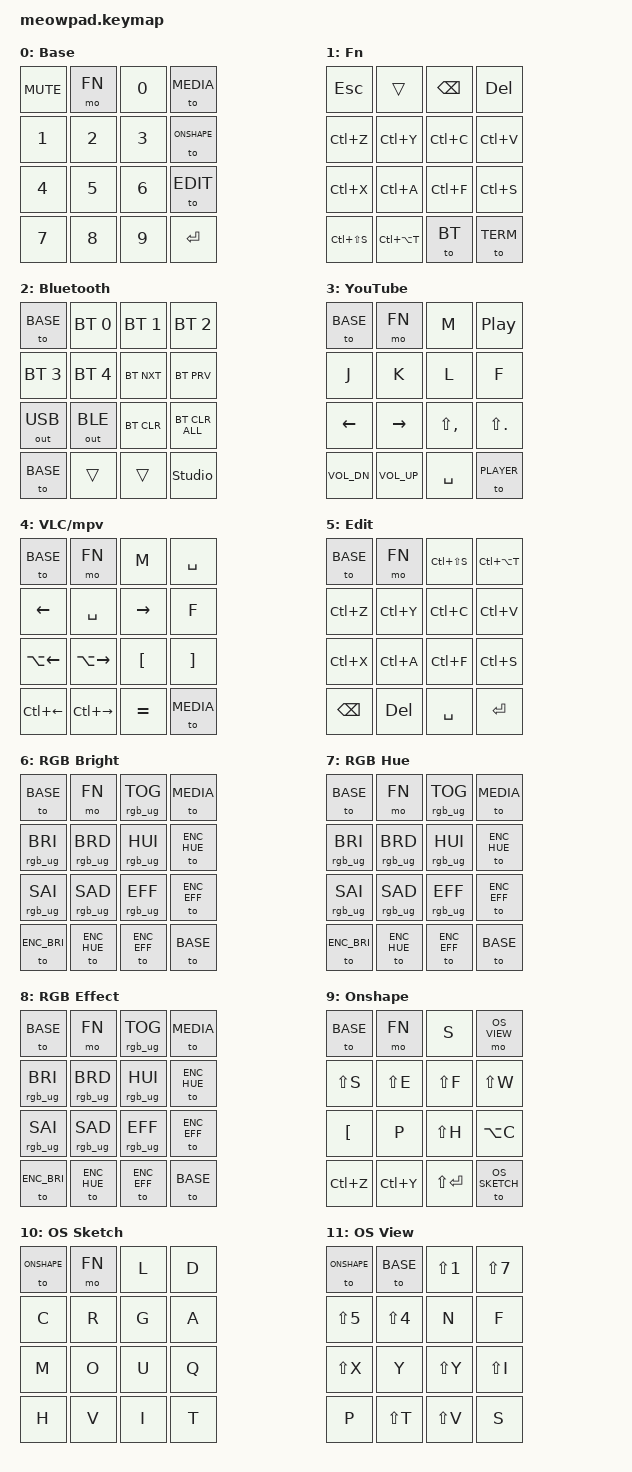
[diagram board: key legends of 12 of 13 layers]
#include <behaviors.dtsi>
#include <dt-bindings/zmk/bt.h>
#include <dt-bindings/zmk/keys.h>
#include <dt-bindings/zmk/outputs.h>
#include <dt-bindings/zmk/rgb.h>

#define BASE       0
#define FN         1
#define BT         2
#define MEDIA      3
#define PLAYER     4
#define EDIT       5
#define ENC_BRI    6
#define ENC_HUE    7
#define ENC_EFF    8
#define ONSHAPE    9
#define OS_SKETCH  10
#define OS_VIEW    11
#define TERM       12

/*
 * Debug override for encoder bring-up. This keeps the shield overlay as-is
 * while forcing the tested P0.29/P0.31 pin order and a very obvious step rate.
 */
&encoder {
    a-gpios = <&pro_micro 20 (GPIO_ACTIVE_HIGH | GPIO_PULL_UP)>; /* D20/A2 -> P0.29 */
    b-gpios = <&pro_micro 21 (GPIO_ACTIVE_HIGH | GPIO_PULL_UP)>; /* D21/A3 -> P0.31 */
    steps = <80>;
};

/ {
    behaviors {
        rgb_encoder_bri: rgb_encoder_bri {
            compatible = "zmk,behavior-sensor-rotate";
            #sensor-binding-cells = <0>;
            bindings = <&rgb_ug RGB_BRI>, <&rgb_ug RGB_BRD>;
        };

        rgb_encoder_hue: rgb_encoder_hue {
            compatible = "zmk,behavior-sensor-rotate";
            #sensor-binding-cells = <0>;
            bindings = <&rgb_ug RGB_HUI>, <&rgb_ug RGB_HUD>;
        };

        rgb_encoder_eff: rgb_encoder_eff {
            compatible = "zmk,behavior-sensor-rotate";
            #sensor-binding-cells = <0>;
            bindings = <&rgb_ug RGB_EFF>, <&rgb_ug RGB_EFR>;
        };

        onshape_zoom_encoder: onshape_zoom_encoder {
            compatible = "zmk,behavior-sensor-rotate";
            #sensor-binding-cells = <0>;
            bindings = <&kp LS(Z)>, <&kp Z>;
        };
    };

    macros {
        term_fg: term_fg {
            compatible = "zmk,behavior-macro";
            #binding-cells = <0>;
            bindings = <&macro_tap &kp F &kp G &kp ENTER>;
        };

        term_ls: term_ls {
            compatible = "zmk,behavior-macro";
            #binding-cells = <0>;
            bindings = <&macro_tap &kp L &kp S &kp SPACE &kp MINUS &kp L &kp A &kp H &kp ENTER>;
        };

        term_cd_up: term_cd_up {
            compatible = "zmk,behavior-macro";
            #binding-cells = <0>;
            bindings = <&macro_tap &kp C &kp D &kp SPACE &kp DOT &kp DOT &kp ENTER>;
        };

        term_git_status: term_git_status {
            compatible = "zmk,behavior-macro";
            #binding-cells = <0>;
            bindings = <&macro_tap &kp G &kp I &kp T &kp SPACE &kp S &kp T &kp A &kp T &kp U &kp S &kp ENTER>;
        };
    };

    keymap {
        compatible = "zmk,keymap";

        /*
         * Physical cap legend shared by all layers:
         *
         * | knob | fn | 0 | m1 |
         * |  1   | 2  | 3 | m2 |
         * |  4   | 5  | 6 | m3 |
         * |  7   | 8  | 9 | m4 |
         */

        default_layer {
            display-name = "Base";
            /*
             * Base layer:
             *
             * |mute | fn | 0 | media |
             * |  1  | 2  | 3 | onshp |
             * |  4  | 5  | 6 | edit  |
             * |  7  | 8  | 9 | enter |
             *
             * Encoder rotate: volume up/down.
             */
            bindings = <
                &kp C_MUTE       &mo FN          &kp N0          &to MEDIA
                &kp N1           &kp N2          &kp N3          &to ONSHAPE
                &kp N4           &kp N5          &kp N6          &to EDIT
                &kp N7           &kp N8          &kp N9          &kp ENTER
            >;
            sensor-bindings = <&inc_dec_kp C_VOL_UP C_VOL_DN>;
        };


        fn_layer {
            /*
             * Function layer:
             *
             * |esc | --- | bspc | del  |
             * |undo| redo| copy | paste|
             * | cut| all | find | save |
             * |snip| term| bt   | term |
             */
            display-name = "Fn";
            bindings = <
                &kp ESC          &trans          &kp BSPC        &kp DEL
                &kp LC(Z)        &kp LC(Y)       &kp LC(C)       &kp LC(V)
                &kp LC(X)        &kp LC(A)       &kp LC(F)       &kp LC(S)
                &kp LC(LS(S))    &kp LC(LA(T))   &to BT          &to TERM
            >;
            sensor-bindings = <&inc_dec_kp C_VOL_UP C_VOL_DN>;
        };

        bluetooth_layer {
            /*
             * Bluetooth/output layer:
             *
             * |base | bt0 | bt1 | bt2     |
             * | bt3 | bt4 | next| prev    |
             * | usb | ble | clr | clr_all |
             * |base | --- | --- | studio  |
             */
            display-name = "Bluetooth";
            bindings = <
                &to BASE         &bt BT_SEL 0    &bt BT_SEL 1    &bt BT_SEL 2
                &bt BT_SEL 3     &bt BT_SEL 4    &bt BT_NXT      &bt BT_PRV
                &out OUT_USB     &out OUT_BLE    &bt BT_CLR      &bt BT_CLR_ALL
                &to BASE         &trans          &trans          &studio_unlock
            >;
            sensor-bindings = <&inc_dec_kp C_VOL_UP C_VOL_DN>;
        };

        media_layer {

            /*
             * YouTube/media layer:
             *
             * |base | fn | mute | play  |
             * |  j  | k  |  l   | full  |
             * |left |right| <   | >     |
             * |vol- |vol+| space| player|
             *
             * Encoder rotate: volume up/down.
             */
            display-name = "YouTube";
            bindings = <
                &to BASE         &mo FN          &kp M           &kp C_PP
                &kp J            &kp K           &kp L           &kp F
                &kp LEFT         &kp RIGHT       &kp LS(COMMA)   &kp LS(DOT)
                &kp C_VOL_DN     &kp C_VOL_UP    &kp SPACE       &to PLAYER
            >;
            sensor-bindings = <&inc_dec_kp C_VOL_UP C_VOL_DN>;
        };

        player_layer {

            /*
             * VLC/mpv player layer:
             *
             * |base | fn | mute | play  |
             * |left |space|right| full  |
             * |a-left|a-right| [ | ]    |
             * |c-left|c-right| = | media|
             *
             * Encoder rotate: volume up/down.
             */
            display-name = "VLC/mpv";
            bindings = <
                &to BASE         &mo FN          &kp M           &kp SPACE
                &kp LEFT         &kp SPACE       &kp RIGHT       &kp F
                &kp LA(LEFT)     &kp LA(RIGHT)   &kp LBKT        &kp RBKT
                &kp LC(LEFT)     &kp LC(RIGHT)   &kp EQUAL       &to MEDIA
            >;
            sensor-bindings = <&inc_dec_kp C_VOL_UP C_VOL_DN>;
        };

        edit_layer {

            /*
             * Edit layer:
             *
             * |base | fn | snip | term |
             * |undo |redo| copy |paste |
             * | cut | all| find |save  |
             * |bspc |del |space |enter |
             */
            display-name = "Edit";
            bindings = <
                &to BASE         &mo FN          &kp LC(LS(S))   &kp LC(LA(T))
                &kp LC(Z)        &kp LC(Y)       &kp LC(C)       &kp LC(V)
                &kp LC(X)        &kp LC(A)       &kp LC(F)       &kp LC(S)
                &kp BSPC         &kp DEL         &kp SPACE       &kp ENTER
            >;
            sensor-bindings = <&inc_dec_kp C_VOL_UP C_VOL_DN>;
        };

        encoder_brightness_layer {
            /*
             * RGB brightness mode:
             *
             * |base | fn | rgb  | media |
             * | bri | brd| hue+ | hue   |
             * | sat+| sat-| eff | effect|
             * | bri | hue| effect| base |
             *
             * Encoder rotate: brightness up/down.
             */
            display-name = "RGB Bright";
            bindings = <
                &to BASE         &mo FN          &rgb_ug RGB_TOG &to MEDIA
                &rgb_ug RGB_BRI  &rgb_ug RGB_BRD &rgb_ug RGB_HUI &to ENC_HUE
                &rgb_ug RGB_SAI  &rgb_ug RGB_SAD &rgb_ug RGB_EFF &to ENC_EFF
                &to ENC_BRI      &to ENC_HUE     &to ENC_EFF     &to BASE
            >;
            sensor-bindings = <&rgb_encoder_bri>;
        };

        encoder_hue_layer {
            /*
             * RGB hue mode.
             * Same key layout as RGB Bright; only the encoder action changes.
             * Encoder rotate: hue up/down.
             */
            display-name = "RGB Hue";
            bindings = <
                &to BASE         &mo FN          &rgb_ug RGB_TOG &to MEDIA
                &rgb_ug RGB_BRI  &rgb_ug RGB_BRD &rgb_ug RGB_HUI &to ENC_HUE
                &rgb_ug RGB_SAI  &rgb_ug RGB_SAD &rgb_ug RGB_EFF &to ENC_EFF
                &to ENC_BRI      &to ENC_HUE     &to ENC_EFF     &to BASE
            >;
            sensor-bindings = <&rgb_encoder_hue>;
        };

        encoder_effect_layer {
            /*
             * RGB effect mode.
             * Same key layout as RGB Bright; only the encoder action changes.
             * Encoder rotate: effect next/previous.
             */
            display-name = "RGB Effect";
            bindings = <
                &to BASE         &mo FN          &rgb_ug RGB_TOG &to MEDIA
                &rgb_ug RGB_BRI  &rgb_ug RGB_BRD &rgb_ug RGB_HUI &to ENC_HUE
                &rgb_ug RGB_SAI  &rgb_ug RGB_SAD &rgb_ug RGB_EFF &to ENC_EFF
                &to ENC_BRI      &to ENC_HUE     &to ENC_EFF     &to BASE
            >;
            sensor-bindings = <&rgb_encoder_eff>;
        };

        onshape_layer {
            /*
             * Onshape main layer:
             *
             * |base | fn |   s     | view |
             * |sh+s |sh+e| sh+f    | sh+w |
             * |  [  | p  | sh+h    | alt+c|
             * |undo |redo| sh+enter| sketch|
             *
             * Encoder rotate: zoom out/in.
             */
            display-name = "Onshape";
            bindings = <
                &to BASE         &mo FN          &kp S           &mo OS_VIEW
                &kp LS(S)        &kp LS(E)       &kp LS(F)       &kp LS(W)
                &kp LBKT         &kp P           &kp LS(H)       &kp LA(C)
                &kp LC(Z)        &kp LC(Y)       &kp LS(ENTER)   &to OS_SKETCH
            >;
            sensor-bindings = <&onshape_zoom_encoder>;
        };

        onshape_sketch_layer {
            /*
             * Onshape sketch layer:
             *
             * |main | fn | line | dim |
             * | circ| rect| geom | arc |
             * | move| offs| use  | slot|
             * | trim| fillet| infer| text |
             *
             * Encoder rotate: zoom out/in.
             */
            display-name = "OS Sketch";
            bindings = <
                &to ONSHAPE      &mo FN          &kp L           &kp D
                &kp C            &kp R           &kp G           &kp A
                &kp M            &kp O           &kp U           &kp Q
                &kp H            &kp V           &kp I           &kp T
            >;
            sensor-bindings = <&onshape_zoom_encoder>;
        };

        onshape_view_layer {
            /*
             * Onshape view layer:
             *
             * |main | base | sh+1 | sh+7 |
             * |sh+5 | sh+4 |  n   |  f   |
             * |sh+x |  y   | sh+y | sh+i |
             * |  p  | sh+t | sh+v |  s   |
             *
             * Encoder rotate: zoom out/in.
             */
            display-name = "OS View";
            bindings = <
                &to ONSHAPE      &to BASE        &kp LS(N1)      &kp LS(N7)
                &kp LS(N5)       &kp LS(N4)      &kp N           &kp F
                &kp LS(X)        &kp Y           &kp LS(Y)       &kp LS(I)
                &kp P            &kp LS(T)       &kp LS(V)       &kp S
            >;
            sensor-bindings = <&onshape_zoom_encoder>;
        };

        terminal_layer {
            /*
             * Terminal layer:
             *
             * |base | term | tcopy | tpaste |
             * | c-c | c-d  | c-z   |  fg    |
             * | c-a | c-e  | a-b   |  a-f   |
             * | c-u | c-k  | c-w   |  c-r   |
             */
            display-name = "Terminal";
            bindings = <
                &to BASE         &kp LC(LA(T))   &kp LC(LS(C))   &kp LC(LS(V))
                &kp LC(C)        &kp LC(D)       &kp LC(Z)       &term_fg
                &kp LC(A)        &kp LC(E)       &kp LA(B)       &kp LA(F)
                &kp LC(U)        &kp LC(K)       &kp LC(W)       &kp LC(R)
            >;
            sensor-bindings = <&inc_dec_kp C_VOL_UP C_VOL_DN>;
        };

        studio_extra_1 {
            /* Reserved for future ZMK Studio expansion. */
            status = "reserved";
        };

        studio_extra_2 {
            /* Reserved for future ZMK Studio expansion. */
            status = "reserved";
        };

        studio_extra_3 {
            /* Reserved for future ZMK Studio expansion. */
            status = "reserved";
        };
    };
};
